VERSION ""

NS_ :

BS_:

BU_: OpticalSensor SCIMO_PE TelemetryNode Master Sensor Brake PDU TestBench

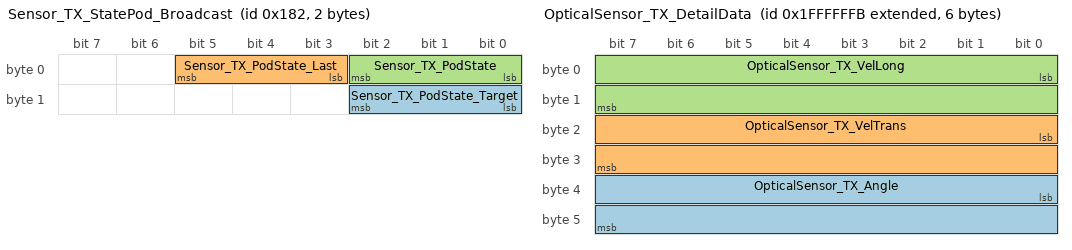
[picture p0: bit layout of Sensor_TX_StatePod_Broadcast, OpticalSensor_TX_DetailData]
BO_ 386 Sensor_TX_StatePod_Broadcast: 2 Vector__XXX
 SG_ Sensor_TX_PodState_Target : 8|3@1+ (1,0) [0|0] "" Vector__XXX
 SG_ Sensor_TX_PodState_Last : 3|3@1+ (1,0) [0|0] "" Vector__XXX
 SG_ Sensor_TX_PodState : 0|3@1+ (1,0) [0|0] "" Vector__XXX

BO_ 1026 Sensor_TX_GapHeight: 4 Vector__XXX
 SG_ Sensor_TX_GapHeight_Right : 12|12@1- (0.0125,0) [-25.6|25.5875] "mm" Vector__XXX
 SG_ Sensor_TX_GapHeight_Left : 0|12@1- (0.0125,0) [-25.6|25.5875] "mm" Vector__XXX

BO_ 450 Sensor_RX_POD1: 8 Vector__XXX

BO_ 2684354555 OpticalSensor_TX_DetailData: 6 OpticalSensor
 SG_ OpticalSensor_TX_Angle : 32|16@1- (0.01,0) [-45|45] "�" Vector__XXX
 SG_ OpticalSensor_TX_VelTrans : 16|16@1- (0.036,0) [-200|200] "km/h" Vector__XXX
 SG_ OpticalSensor_TX_VelLong : 0|16@1+ (0.036,0) [0|400] "km/h" Vector__XXX

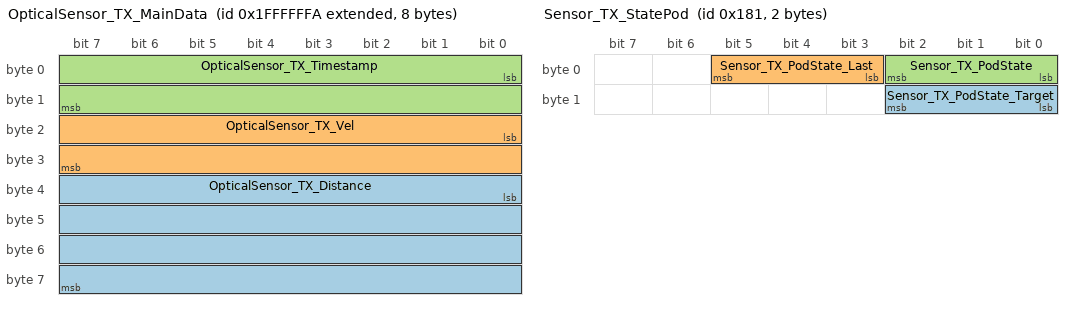
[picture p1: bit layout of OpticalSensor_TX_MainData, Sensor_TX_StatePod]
BO_ 2684354554 OpticalSensor_TX_MainData: 8 OpticalSensor
 SG_ OpticalSensor_TX_Distance : 32|32@1+ (0.001,0) [0|4294970] "m" Vector__XXX
 SG_ OpticalSensor_TX_Vel : 16|16@1+ (0.036,0) [0|400] "km/h" Vector__XXX
 SG_ OpticalSensor_TX_Timestamp : 0|16@1+ (1,0) [0|65535] "" Vector__XXX

BO_ 2684354556 OpticalSensor_TX_Status: 8 OpticalSensor
 SG_ OpticalSensor_TX_VddOK : 62|1@1+ (1,0) [0|0] "" Vector__XXX
 SG_ OpticalSensor_TX_VeeOK : 61|1@1+ (1,0) [0|0] "" Vector__XXX
 SG_ OpticalSensor_TX_V33OK : 60|1@1+ (1,0) [0|0] "" Vector__XXX
 SG_ OpticalSensor_TX_V25OK : 59|1@1+ (1,0) [0|0] "" Vector__XXX
 SG_ OpticalSensor_TX_LEDStatus : 57|2@1+ (1,0) [0|0] "" Vector__XXX
 SG_ OpticalSensor_TX_LED_Cal : 56|1@1+ (1,0) [0|0] "" Vector__XXX
 SG_ OpticalSensor_TX_PowerOK : 55|1@1+ (1,0) [0|0] "" Vector__XXX
 SG_ OpticalSensor_TX_CurrentOK : 54|1@1+ (1,0) [0|0] "" Vector__XXX
 SG_ OpticalSensor_TX_CurrentLowHigh : 53|1@1+ (1,0) [0|0] "" Vector__XXX
 SG_ OpticalSensor_TX_OpticOK : 52|1@1+ (1,0) [0|0] "" Vector__XXX
 SG_ OpticalSensor_TX_TempOK : 51|1@1+ (1,0) [0|0] "" Vector__XXX
 SG_ OpticalSensor_TX_SensorOK : 50|1@1+ (1,0) [0|0] "" Vector__XXX
 SG_ OpticalSensor_TX_SelfTest : 49|1@1+ (1,0) [0|0] "" Vector__XXX
 SG_ OpticalSensor_TX_STST : 48|1@1+ (1,0) [0|0] "" Vector__XXX
 SG_ OpticalSensor_TX_LEDCurrent : 40|8@1+ (0.01,0) [0|2.55] "A" Vector__XXX
 SG_ OpticalSensor_TX_Temp : 32|8@1- (1,0) [-128|127] "�C" Vector__XXX
 SG_ OpticalSensor_TX_SensorNo : 24|8@1+ (1,0) [0|0] "" Vector__XXX
 SG_ OpticalSensor_TX_SerialNo : 0|24@1+ (1,0) [0|0] "" Vector__XXX

BO_ 2 CANzero_NMT: 4 Master
 SG_ CANzero_NMT_Node : 16|16@1+ (1,0) [0|63] ""  Sensor,Brake,PDU,TelemetryNode
 SG_ CANzero_NMT_State : 0|16@1+ (1,0) [0|0] ""  Sensor,Brake,PDU,TelemetryNode

BO_ 122 CANzero_Sync: 0 Master

BO_ 123 CANzero_Timestamp: 0 Master

BO_ 129 Sensor_EMCY: 4 Sensor

BO_ 385 Sensor_TX_StatePod: 2 Sensor
 SG_ Sensor_TX_PodState_Target : 8|3@1+ (1,0) [0|0] ""  PDU
 SG_ Sensor_TX_PodState_Last : 3|3@1+ (1,0) [0|0] ""  PDU
 SG_ Sensor_TX_PodState : 0|3@1+ (1,0) [0|0] ""  PDU

BO_ 449 Sensor_RX_PDO1: 0 Vector__XXX

BO_ 513 Sensor_TX_FSMTransitions: 4 Sensor
 SG_ Sensor_TX_PreopHVCUT : 24|1@1+ (1,0) [0|0] "" Vector__XXX
 SG_ Sensor_TX_PreopPDUT : 16|1@1+ (1,0) [0|0] "" Vector__XXX
 SG_ Sensor_TX_PreopBrakeRT : 15|1@1+ (1,0) [0|0] "" Vector__XXX
 SG_ Sensor_TX_PreopBrakeFT : 14|1@1+ (1,0) [0|0] "" Vector__XXX
 SG_ Sensor_TX_PreopSensorRT : 13|1@1+ (1,0) [0|0] "" Vector__XXX
 SG_ Sensor_TX_EnableSensorRT : 12|1@1+ (1,0) [0|0] "" Vector__XXX
 SG_ Sensor_TX_EnablePDUT : 11|1@1+ (1,0) [0|0] "" Vector__XXX
 SG_ Sensor_TX_EnableHVCUT : 10|1@1+ (1,0) [0|0] "" Vector__XXX
 SG_ Sensor_TX_EnableBrakeRT : 9|1@1+ (1,0) [0|0] "" Vector__XXX
 SG_ Sensor_TX_EnableBrakeFT : 8|1@1+ (1,0) [0|0] "" Vector__XXX
 SG_ Sensor_TX_SetHVTransition : 7|1@1+ (1,0) [0|0] "" Vector__XXX
 SG_ Sensor_TX_PreopTransition : 6|1@1+ (1,0) [0|0] "" Vector__XXX
 SG_ Sensor_TX_LaunchStartTransition : 5|1@1+ (1,0) [0|0] "" Vector__XXX
 SG_ Sensor_TX_LaunchSetupTransition : 4|1@1+ (1,0) [0|0] "" Vector__XXX
 SG_ Sensor_TX_HWEnableTransition : 3|1@1+ (1,0) [0|0] "" Vector__XXX
 SG_ Sensor_TX_ErrorResetTransition : 2|1@1+ (1,0) [0|0] "" Vector__XXX
 SG_ Sensor_TX_EnableTransition : 1|1@1+ (1,0) [0|0] "" Vector__XXX
 SG_ Sensor_TX_BrakesTransition : 0|1@1+ (1,0) [0|0] "" Vector__XXX

BO_ 577 Sensor_RX_PDO2: 0 Vector__XXX

BO_ 641 Sensor_TX_PDO3: 0 Sensor

BO_ 705 Sensor_RX_PDO3: 0 Vector__XXX

BO_ 769 Sensor_TX_PDO4: 0 Sensor

BO_ 833 Sensor_RX_PDO4: 0 Vector__XXX

BO_ 897 Sensor_TX_PDO5: 0 Sensor

BO_ 961 Sensor_TX_PDO6: 0 Sensor

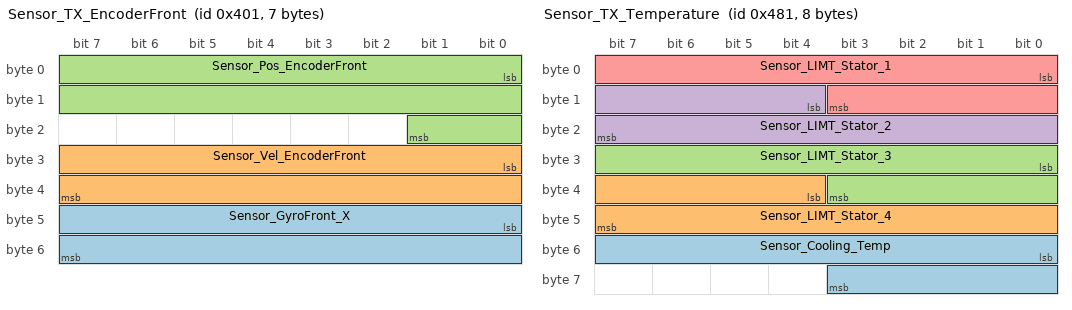
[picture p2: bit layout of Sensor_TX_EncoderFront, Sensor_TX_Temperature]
BO_ 1025 Sensor_TX_EncoderFront: 7 Sensor
 SG_ Sensor_GyroFront_X : 40|16@1- (0.017,0) [-557.056|557.039] "°/s" Vector__XXX
 SG_ Sensor_Vel_EncoderFront : 24|16@1- (0.002,0) [-65.536|65.534] "m/s" Vector__XXX
 SG_ Sensor_Pos_EncoderFront : 0|18@1- (0.005,0) [-655.36|655.355] "m" Vector__XXX

BO_ 1089 Sensor_TX_BMS: 2 Sensor
 SG_ Sensor_TX_BatteryTemp : 0|12@1+ (0.05,-30) [-30|174.75] "C"  PDU

BO_ 1153 Sensor_TX_Temperature: 8 Sensor
 SG_ Sensor_Cooling_Temp : 48|12@1+ (0.05,-30) [-30|174.75] "C"  PDU
 SG_ Sensor_LIMT_Stator_4 : 36|12@1+ (0.075,-20) [-20|287.125] "�C" Vector__XXX
 SG_ Sensor_LIMT_Stator_3 : 24|12@1+ (0.075,-20) [-20|287.125] "�C" Vector__XXX
 SG_ Sensor_LIMT_Stator_2 : 12|12@1+ (0.075,-20) [-20|287.125] "�C" Vector__XXX
 SG_ Sensor_LIMT_Stator_1 : 0|12@1+ (0.075,-20) [-20|287.125] "�C" Vector__XXX

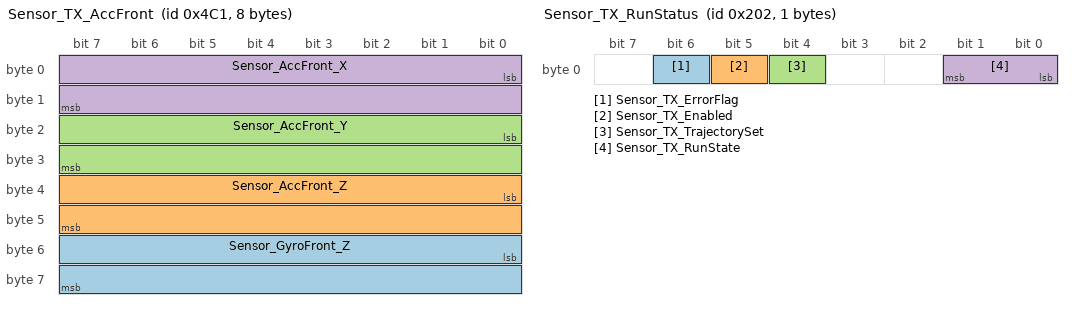
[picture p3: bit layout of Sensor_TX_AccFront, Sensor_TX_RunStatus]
BO_ 1217 Sensor_TX_AccFront: 8 Sensor
 SG_ Sensor_GyroFront_Z : 48|16@1- (0.017,0) [-557.056|557.039] "°/s" Vector__XXX
 SG_ Sensor_AccFront_Z : 32|16@1- (0.00125,0) [-40.96|40.95875] "m/s^2" Vector__XXX
 SG_ Sensor_AccFront_Y : 16|16@1- (0.00125,0) [-40.96|40.95875] "m/s^2" Vector__XXX
 SG_ Sensor_AccFront_X : 0|16@1- (0.00125,0) [-40.96|40.95875] "m/s^2" Vector__XXX

BO_ 1281 Sensor_TX_PDO11: 0 Sensor

BO_ 1345 Sensor_TX_PDO12: 0 Sensor

BO_ 1409 Sensor_SDO_Resp: 8 Sensor
 SG_ Sensor_SDO_RespCode : 12|4@1+ (1,0) [0|0] ""  TelemetryNode
 SG_ Sensor_SDO_ID M : 0|12@1+ (1,0) [0|4095] ""  TelemetryNode

BO_ 1473 Sensor_SDO_Req_Up: 8 TelemetryNode
 SG_ Sensor_SDO_ID M : 0|12@1+ (1,0) [0|4095] ""  Sensor

BO_ 1537 Sensor_SDO_Req_Down: 2 TelemetryNode
 SG_ Sensor_SDO_ID M : 0|12@1+ (1,0) [0|4095] ""  Sensor

BO_ 1793 Sensor_Heartbeat: 1 Sensor
 SG_ Sensor_NodeState : 0|8@1+ (1,0) [0|0] ""  Sensor,Master,TelemetryNode

BO_ 1857 Sensor_BTL_TX: 8 Sensor

BO_ 1921 Sensor_BTL_RX: 8 TelemetryNode

BO_ 514 Sensor_TX_RunStatus: 1 Vector__XXX
 SG_ Sensor_TX_ErrorFlag : 6|1@1+ (1,0) [0|0] ""  Sensor
 SG_ Sensor_TX_Enabled : 5|1@1+ (1,0) [0|0] ""  Sensor
 SG_ Sensor_TX_TrajectorySet : 4|1@1+ (1,0) [0|0] "" Vector__XXX
 SG_ Sensor_TX_RunState : 0|2@1+ (1,0) [0|0] ""  PDU,Sensor

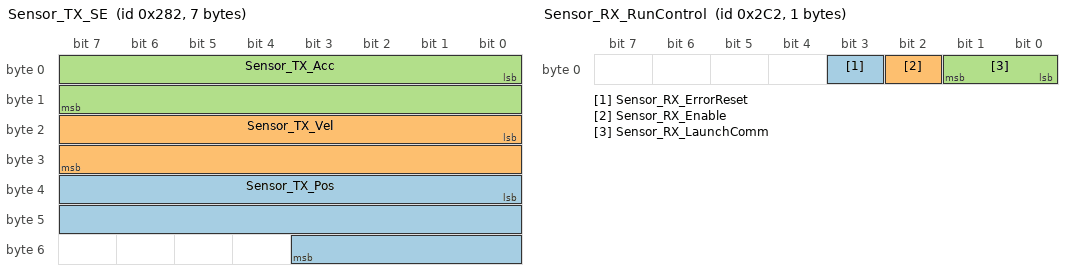
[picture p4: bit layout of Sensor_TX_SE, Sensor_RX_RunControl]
BO_ 642 Sensor_TX_SE: 7 Vector__XXX
 SG_ Sensor_TX_Pos : 32|20@1- (0.001,0) [-524.288|524.287] "m"  PDU,TelemetryNode
 SG_ Sensor_TX_Vel : 16|16@1- (0.002,0) [-65.536|65.534] "m/s"  PDU,TelemetryNode
 SG_ Sensor_TX_Acc : 0|16@1- (0.00125,0) [-40.96|40.95875] "m/s^2"  PDU,TelemetryNode

BO_ 706 Sensor_RX_RunControl: 1 Sensor
 SG_ Sensor_RX_ErrorReset : 3|1@1+ (1,0) [0|0] "" Vector__XXX
 SG_ Sensor_RX_Enable : 2|1@1+ (1,0) [0|0] "" Vector__XXX
 SG_ Sensor_RX_LaunchComm : 0|2@1+ (1,0) [0|0] "" Vector__XXX

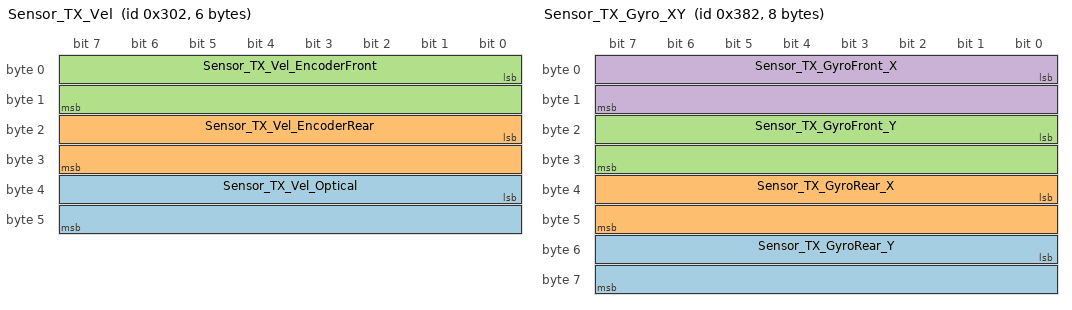
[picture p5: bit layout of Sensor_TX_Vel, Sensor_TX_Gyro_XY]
BO_ 770 Sensor_TX_Vel: 6 Vector__XXX
 SG_ Sensor_TX_Vel_Optical : 32|16@1- (0.002,0) [-65.536|65.534] "m/s" Vector__XXX
 SG_ Sensor_TX_Vel_EncoderRear : 16|16@1- (0.002,0) [-65.536|65.534] "m/s" Vector__XXX
 SG_ Sensor_TX_Vel_EncoderFront : 0|16@1- (0.002,0) [-65.536|65.534] "m/s" Vector__XXX

BO_ 898 Sensor_TX_Gyro_XY: 8 Vector__XXX
 SG_ Sensor_TX_GyroRear_Y : 48|16@1- (0.017,0) [-557.056|557.039] "°/s" Vector__XXX
 SG_ Sensor_TX_GyroRear_X : 32|16@1- (0.017,0) [-557.056|557.039] "°/s" Vector__XXX
 SG_ Sensor_TX_GyroFront_Y : 16|16@1- (0.017,0) [-557.056|557.039] "°/s" Vector__XXX
 SG_ Sensor_TX_GyroFront_X : 0|16@1- (0.017,0) [-557.056|557.039] "°/s" Vector__XXX

BO_ 962 Sensor_TX_TargetValues: 2 Vector__XXX
 SG_ Sensor_TX_TargetVelocity : 0|14@1- (0.01,0) [-81.92|81.91] "m/s" Vector__XXX

BO_ 1090 Sensor_TX_PDO8: 0 Vector__XXX

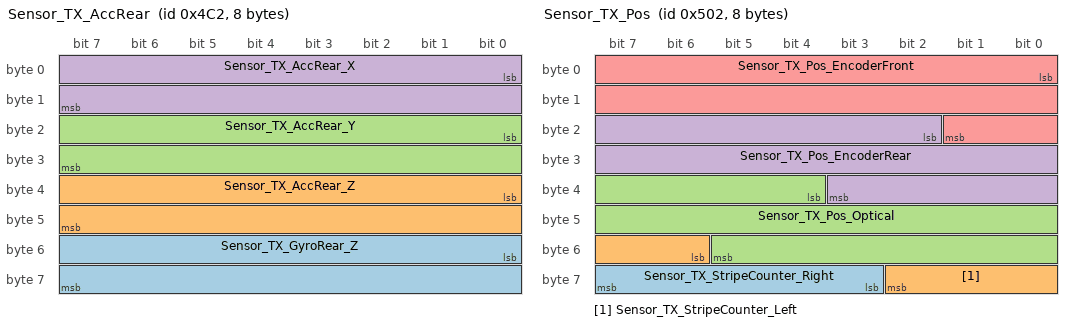
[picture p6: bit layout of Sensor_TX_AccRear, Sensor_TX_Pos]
BO_ 1218 Sensor_TX_AccRear: 8 Vector__XXX
 SG_ Sensor_TX_GyroRear_Z : 48|16@1- (0.017,0) [-557.056|557.039] "°/s" Vector__XXX
 SG_ Sensor_TX_AccRear_Z : 32|16@1- (0.00125,0) [-40.96|40.95875] "m/s^2" Vector__XXX
 SG_ Sensor_TX_AccRear_Y : 16|16@1- (0.00125,0) [-40.96|40.95875] "m/s^2" Vector__XXX
 SG_ Sensor_TX_AccRear_X : 0|16@1- (0.00125,0) [-40.96|40.95875] "m/s^2" Vector__XXX

BO_ 1282 Sensor_TX_Pos: 8 Vector__XXX
 SG_ Sensor_TX_StripeCounter_Right : 59|5@1+ (1,0) [0|31] "" Vector__XXX
 SG_ Sensor_TX_StripeCounter_Left : 54|5@1+ (1,0) [0|31] "" Vector__XXX
 SG_ Sensor_TX_Pos_Optical : 36|18@1- (0.005,0) [-655.36|655.355] "m" Vector__XXX
 SG_ Sensor_TX_Pos_EncoderRear : 18|18@1- (0.005,0) [-655.36|655.355] "m" Vector__XXX
 SG_ Sensor_TX_Pos_EncoderFront : 0|18@1- (0.005,0) [-655.36|655.355] "m" Vector__XXX

BO_ 145 Brake_EMCY: 4 Brake

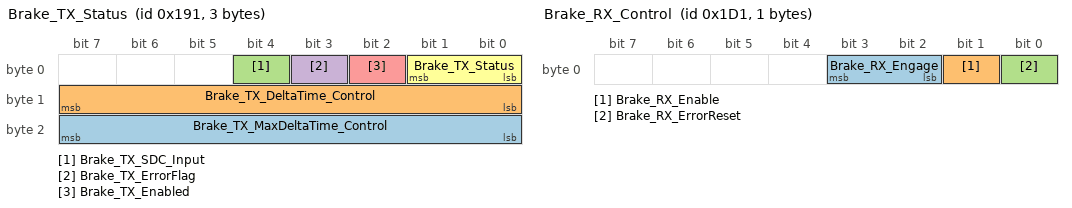
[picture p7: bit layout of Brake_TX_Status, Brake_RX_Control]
BO_ 401 Brake_TX_Status: 3 Brake
 SG_ Brake_TX_MaxDeltaTime_Control : 16|8@1+ (1,0) [0|255] "ms" Vector__XXX
 SG_ Brake_TX_DeltaTime_Control : 8|8@1+ (1,0) [0|255] "ms" Vector__XXX
 SG_ Brake_TX_SDC_Input : 4|1@1+ (1,0) [0|0] "" Vector__XXX
 SG_ Brake_TX_ErrorFlag : 3|1@1+ (1,0) [0|0] ""  Sensor
 SG_ Brake_TX_Enabled : 2|1@1+ (1,0) [0|0] ""  Sensor
 SG_ Brake_TX_Status : 0|2@1+ (1,0) [0|0] ""  Sensor

BO_ 465 Brake_RX_Control: 1 Sensor
 SG_ Brake_RX_Engage : 2|2@1+ (1,0) [0|0] "" Vector__XXX
 SG_ Brake_RX_Enable : 1|1@1+ (1,0) [0|0] "" Vector__XXX
 SG_ Brake_RX_ErrorReset : 0|1@1+ (1,0) [0|0] "" Vector__XXX

BO_ 529 Brake_TX_PDO2: 0 Brake

BO_ 593 Brake_RX_PDO2: 0 Vector__XXX

BO_ 657 Brake_TX_PDO3: 0 Brake

BO_ 721 Brake_RX_PDO3: 0 Vector__XXX

BO_ 785 Brake_TX_PDO4: 0 Brake

BO_ 849 Brake_RX_PDO4: 0 Vector__XXX

BO_ 913 Brake_TX_PDO5: 0 Brake

BO_ 977 Brake_TX_PDO6: 0 Brake

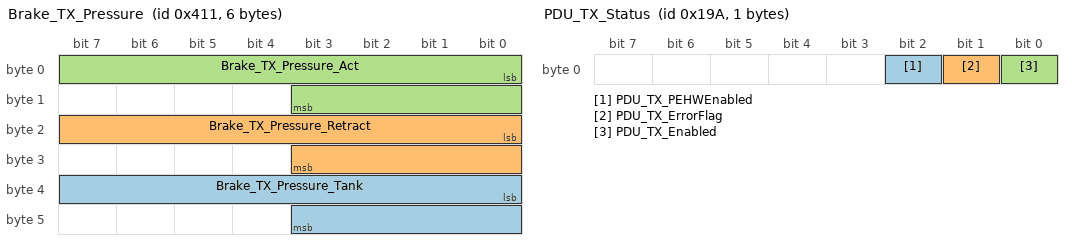
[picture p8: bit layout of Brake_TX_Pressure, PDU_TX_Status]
BO_ 1041 Brake_TX_Pressure: 6 Brake
 SG_ Brake_TX_Pressure_Tank : 32|12@1+ (0.005,-2) [-2|18.475] "bar" Vector__XXX
 SG_ Brake_TX_Pressure_Retract : 16|12@1+ (0.005,-2) [-2|18.475] "bar" Vector__XXX
 SG_ Brake_TX_Pressure_Act : 0|12@1+ (0.005,-2) [-2|18.475] "bar" Vector__XXX

BO_ 1105 Brake_TX_PDO8: 0 Brake

BO_ 1169 Brake_TX_PDO9: 0 Brake

BO_ 1233 Brake_TX_PDO10: 0 Brake

BO_ 1297 Brake_TX_PDO11: 0 Brake

BO_ 1361 Brake_TX_PDO12: 0 Brake

BO_ 1425 Brake_SDO_Resp: 8 Brake
 SG_ Brake_SDO_RespCode : 12|4@1+ (1,0) [0|0] ""  TelemetryNode
 SG_ Brake_SDO_ID M : 0|12@1+ (1,0) [0|4095] ""  TelemetryNode

BO_ 1489 Brake_SDO_Req_Up: 8 TelemetryNode
 SG_ Brake_SDO_ID M : 0|12@1+ (1,0) [0|4095] ""  Brake

BO_ 1553 Brake_SDO_Req_Down: 2 TelemetryNode
 SG_ Brake_SDO_ID M : 0|12@1+ (1,0) [0|4095] ""  Brake

BO_ 1809 Brake_Heartbeat: 1 Brake
 SG_ Brake_NodeState : 0|8@1+ (1,0) [0|0] ""  Sensor,Master,TelemetryNode

BO_ 1873 Brake_BTL_TX: 8 Brake

BO_ 1937 Brake_BTL_RX: 8 TelemetryNode

BO_ 154 PDU_EMCY: 4 PDU

BO_ 410 PDU_TX_Status: 1 PDU
 SG_ PDU_TX_PEHWEnabled : 2|1@1+ (1,0) [0|0] ""  Sensor
 SG_ PDU_TX_ErrorFlag : 1|1@1+ (1,0) [0|0] ""  Sensor
 SG_ PDU_TX_Enabled : 0|1@1+ (1,0) [0|0] ""  Sensor

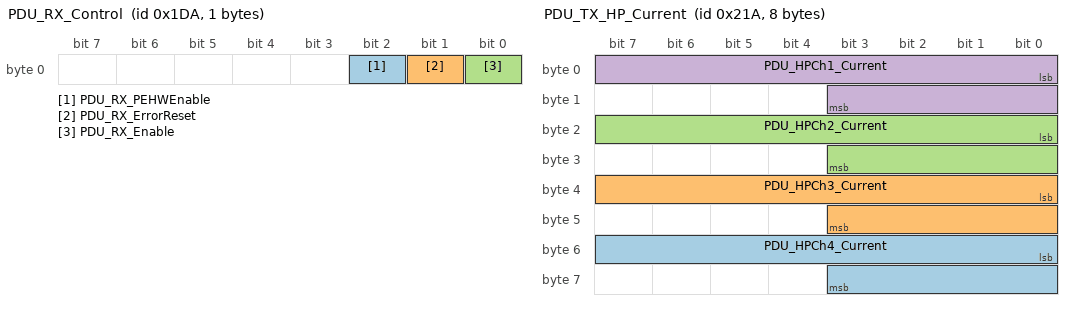
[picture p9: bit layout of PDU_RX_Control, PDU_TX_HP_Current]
BO_ 474 PDU_RX_Control: 1 Sensor
 SG_ PDU_RX_PEHWEnable : 2|1@1+ (1,0) [0|0] "" Vector__XXX
 SG_ PDU_RX_ErrorReset : 1|1@1+ (1,0) [0|0] "" Vector__XXX
 SG_ PDU_RX_Enable : 0|1@1+ (1,0) [0|0] "" Vector__XXX

BO_ 538 PDU_TX_HP_Current: 8 PDU
 SG_ PDU_HPCh4_Current : 48|12@1+ (0.004,0) [0|16.38] "A" Vector__XXX
 SG_ PDU_HPCh3_Current : 32|12@1+ (0.004,0) [0|16.38] "A" Vector__XXX
 SG_ PDU_HPCh2_Current : 16|12@1+ (0.004,0) [0|16.38] "A" Vector__XXX
 SG_ PDU_HPCh1_Current : 0|12@1+ (0.004,0) [0|16.38] "A" Vector__XXX

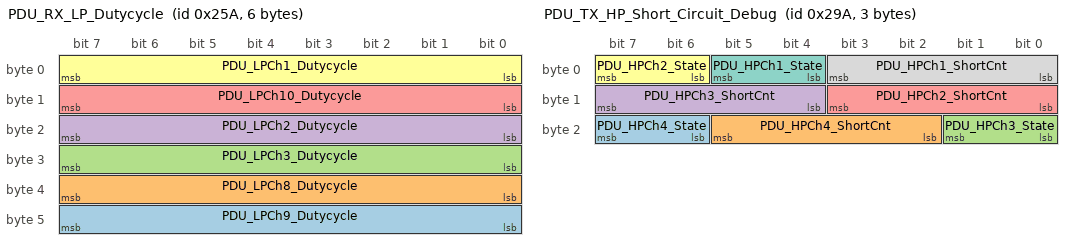
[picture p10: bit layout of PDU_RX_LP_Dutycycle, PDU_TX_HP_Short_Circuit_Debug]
BO_ 602 PDU_RX_LP_Dutycycle: 6 Vector__XXX
 SG_ PDU_LPCh9_Dutycycle : 40|8@1+ (0.5,0) [0|100] "%" Vector__XXX
 SG_ PDU_LPCh8_Dutycycle : 32|8@1+ (0.5,0) [0|100] "%" Vector__XXX
 SG_ PDU_LPCh3_Dutycycle : 24|8@1+ (0.5,0) [0|100] "%" Vector__XXX
 SG_ PDU_LPCh2_Dutycycle : 16|8@1+ (0.5,0) [0|100] "%" Vector__XXX
 SG_ PDU_LPCh10_Dutycycle : 8|8@1+ (0.5,0) [0|100] "%" Vector__XXX
 SG_ PDU_LPCh1_Dutycycle : 0|8@1+ (0.5,0) [0|100] "%" Vector__XXX

BO_ 666 PDU_TX_HP_Short_Circuit_Debug: 3 PDU
 SG_ PDU_HPCh4_State : 22|2@1+ (1,0) [0|3] "" Vector__XXX
 SG_ PDU_HPCh4_ShortCnt : 18|4@1+ (1,0) [0|15] "" Vector__XXX
 SG_ PDU_HPCh3_State : 16|2@1+ (1,0) [0|3] "" Vector__XXX
 SG_ PDU_HPCh3_ShortCnt : 12|4@1+ (1,0) [0|15] "" Vector__XXX
 SG_ PDU_HPCh2_ShortCnt : 8|4@1+ (1,0) [0|15] "" Vector__XXX
 SG_ PDU_HPCh2_State : 6|2@1+ (1,0) [0|3] "" Vector__XXX
 SG_ PDU_HPCh1_State : 4|2@1+ (1,0) [0|3] "" Vector__XXX
 SG_ PDU_HPCh1_ShortCnt : 0|4@1+ (1,0) [0|15] "" Vector__XXX

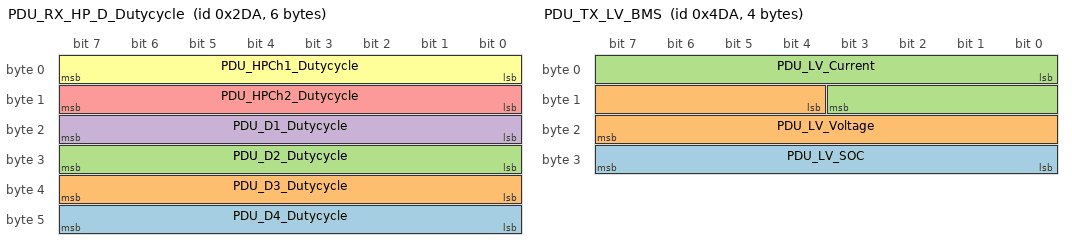
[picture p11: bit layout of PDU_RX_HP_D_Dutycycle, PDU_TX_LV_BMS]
BO_ 730 PDU_RX_HP_D_Dutycycle: 6 Vector__XXX
 SG_ PDU_D4_Dutycycle : 40|8@1+ (0.5,0) [0|100] "%" Vector__XXX
 SG_ PDU_D3_Dutycycle : 32|8@1+ (0.5,0) [0|100] "%" Vector__XXX
 SG_ PDU_D2_Dutycycle : 24|8@1+ (0.5,0) [0|100] "%" Vector__XXX
 SG_ PDU_D1_Dutycycle : 16|8@1+ (0.5,0) [0|100] "%" Vector__XXX
 SG_ PDU_HPCh2_Dutycycle : 8|8@1+ (0.5,0) [0|100] "%" Vector__XXX
 SG_ PDU_HPCh1_Dutycycle : 0|8@1+ (0.5,0) [0|100] "%" Vector__XXX

BO_ 794 PDU_TX_PDO4: 0 PDU

BO_ 858 PDU_RX_Manual_Control: 3 Vector__XXX
 SG_ PDU_SDC_Enable : 18|1@1+ (1,0) [0|0] "" Vector__XXX
 SG_ PDU_D4_Enable : 17|1@1+ (1,0) [0|1] "" Vector__XXX
 SG_ PDU_D3_Enable : 16|1@1+ (1,0) [0|1] "" Vector__XXX
 SG_ PDU_D2_Enable : 15|1@1+ (1,0) [0|1] "" Vector__XXX
 SG_ PDU_D1_Enable : 14|1@1+ (1,0) [0|1] "" Vector__XXX
 SG_ PDU_HPCh4_Enable : 13|1@1+ (1,0) [0|1] "" Vector__XXX
 SG_ PDU_HPCh3_Enable : 12|1@1+ (1,0) [0|1] "" Vector__XXX
 SG_ PDU_HPCh2_Enable : 11|1@1+ (1,0) [0|1] "" Vector__XXX
 SG_ PDU_HPCh1_Enable : 10|1@1+ (1,0) [0|1] "" Vector__XXX
 SG_ PDU_LPCh10_Enable : 9|1@1+ (1,0) [0|1] "" Vector__XXX
 SG_ PDU_LPCh9_Enable : 8|1@1+ (1,0) [0|1] "" Vector__XXX
 SG_ PDU_LPCh8_Enable : 7|1@1+ (1,0) [0|1] "" Vector__XXX
 SG_ PDU_LPCh7_Enable : 6|1@1+ (1,0) [0|1] "" Vector__XXX
 SG_ PDU_LPCh6_Enable : 5|1@1+ (1,0) [0|1] "" Vector__XXX
 SG_ PDU_LPCh5_Enable : 4|1@1+ (1,0) [0|1] "" Vector__XXX
 SG_ PDU_LPCh4_Enable : 3|1@1+ (1,0) [0|1] "" Vector__XXX
 SG_ PDU_LPCh3_Enable : 2|1@1+ (1,0) [0|1] "" Vector__XXX
 SG_ PDU_LPCh2_Enable : 1|1@1+ (1,0) [0|1] "" Vector__XXX
 SG_ PDU_LPCh1_Enable : 0|1@1+ (1,0) [0|1] "" Vector__XXX

BO_ 922 PDU_TX_PDO5: 0 PDU

BO_ 986 PDU_TX_PDO6: 0 PDU

BO_ 1050 PDU_TX_PDO7: 0 PDU

BO_ 1114 PDU_TX_PDO8: 0 PDU

BO_ 1178 PDU_TX_LP_Short_Circuit_Debug: 8 PDU
 SG_ PDU_LPCh9_State : 58|2@1+ (1,0) [0|3] "" Vector__XXX
 SG_ PDU_LPCh8_State : 56|2@1+ (1,0) [0|3] "" Vector__XXX
 SG_ PDU_LPCh7_State : 54|2@1+ (1,0) [0|3] "" Vector__XXX
 SG_ PDU_LPCh6_State : 52|2@1+ (1,0) [0|3] "" Vector__XXX
 SG_ PDU_LPCh5_State : 50|2@1+ (1,0) [0|3] "" Vector__XXX
 SG_ PDU_LPCh4_State : 48|2@1+ (1,0) [0|3] "" Vector__XXX
 SG_ PDU_LPCh3_State : 46|2@1+ (1,0) [0|3] "" Vector__XXX
 SG_ PDU_LPCh2_State : 44|2@1+ (1,0) [0|3] "" Vector__XXX
 SG_ PDU_LPCh1_State : 42|2@1+ (1,0) [0|3] "" Vector__XXX
 SG_ PDU_LPCh10_State : 40|2@1+ (1,0) [0|3] "" Vector__XXX
 SG_ PDU_LPCh9_ShortCnt : 36|4@1+ (1,0) [0|15] "" Vector__XXX
 SG_ PDU_LPCh8_ShortCnt : 32|4@1+ (1,0) [0|15] "" Vector__XXX
 SG_ PDU_LPCh7_ShortCnt : 28|4@1+ (1,0) [0|15] "" Vector__XXX
 SG_ PDU_LPCh6_ShortCnt : 24|4@1+ (1,0) [0|15] "" Vector__XXX
 SG_ PDU_LPCh5_ShortCnt : 20|4@1+ (1,0) [0|15] "" Vector__XXX
 SG_ PDU_LPCh4_ShortCnt : 16|4@1+ (1,0) [0|15] "" Vector__XXX
 SG_ PDU_LPCh3_ShortCnt : 12|4@1+ (1,0) [0|15] "" Vector__XXX
 SG_ PDU_LPCh2_ShortCnt : 8|4@1+ (1,0) [0|15] "" Vector__XXX
 SG_ PDU_LPCh1_ShortCnt : 4|4@1+ (1,0) [0|15] "" Vector__XXX
 SG_ PDU_LPCh10_ShortCnt : 0|4@1+ (1,0) [0|15] "" Vector__XXX

BO_ 1242 PDU_TX_LV_BMS: 4 PDU
 SG_ PDU_LV_SOC : 24|8@1- (1,0) [0|100] "%" Vector__XXX
 SG_ PDU_LV_Voltage : 12|12@1+ (0.01,0) [0|40.95] "V" Vector__XXX
 SG_ PDU_LV_Current : 0|12@1+ (0.01,0) [0|40.95] "A" Vector__XXX

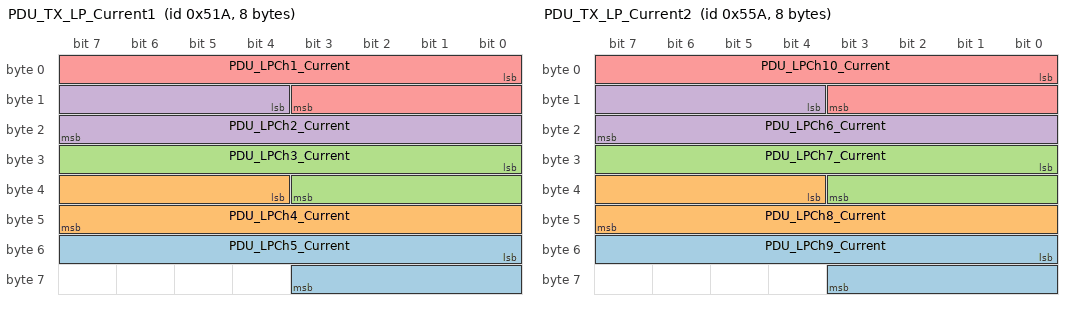
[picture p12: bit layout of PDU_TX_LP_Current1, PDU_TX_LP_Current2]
BO_ 1306 PDU_TX_LP_Current1: 8 PDU
 SG_ PDU_LPCh5_Current : 48|12@1+ (0.002,0) [0|8.19] "A" Vector__XXX
 SG_ PDU_LPCh4_Current : 36|12@1+ (0.002,0) [0|8.19] "A" Vector__XXX
 SG_ PDU_LPCh3_Current : 24|12@1+ (0.002,0) [0|8.19] "A" Vector__XXX
 SG_ PDU_LPCh2_Current : 12|12@1+ (0.002,0) [0|8.19] "A" Vector__XXX
 SG_ PDU_LPCh1_Current : 0|12@1+ (0.002,0) [0|8.19] "A" Vector__XXX

BO_ 1370 PDU_TX_LP_Current2: 8 PDU
 SG_ PDU_LPCh9_Current : 48|12@1+ (0.002,0) [0|8.19] "A" Vector__XXX
 SG_ PDU_LPCh8_Current : 36|12@1+ (0.002,0) [0|8.19] "A" Vector__XXX
 SG_ PDU_LPCh7_Current : 24|12@1+ (0.002,0) [0|8.19] "A" Vector__XXX
 SG_ PDU_LPCh6_Current : 12|12@1+ (0.002,0) [0|8.19] "A" Vector__XXX
 SG_ PDU_LPCh10_Current : 0|12@1+ (0.002,0) [0|8.19] "A" Vector__XXX

BO_ 1434 PDU_SDO_Resp: 8 PDU
 SG_ PDU_SDO_RespCode : 12|4@1+ (1,0) [0|0] ""  TelemetryNode
 SG_ PDU_SDO_ID M : 0|12@1+ (1,0) [0|4095] ""  TelemetryNode

BO_ 1498 PDU_SDO_Req_Up: 8 TelemetryNode
 SG_ PDU_SDO_ID M : 0|12@1+ (1,0) [0|4095] ""  PDU

BO_ 1562 PDU_SDO_Req_Down: 2 TelemetryNode
 SG_ PDU_SDO_ID M : 0|12@1+ (1,0) [0|4095] ""  PDU

BO_ 1818 PDU_Heartbeat: 1 PDU
 SG_ PDU_NodeState : 0|8@1+ (1,0) [0|0] ""  Sensor,Master,TelemetryNode

BO_ 1882 PDU_BTL_TX: 8 PDU

BO_ 1946 PDU_BTL_RX: 8 TelemetryNode

BO_ 162 TelemetryNode_EMCY: 4 TelemetryNode

BO_ 418 TelemetryNode_TX_PDO1: 0 TelemetryNode

BO_ 482 TelemetryNode_RX_Shutdown: 1 Vector__XXX
 SG_ TelemetryNode_RX_Shutdown : 0|8@1+ (1,0) [0|0] "" Vector__XXX

BO_ 546 TelemetryNode_TX_PDO2: 0 TelemetryNode

BO_ 610 TelemetryNode_RX_PDO2: 0 Vector__XXX

BO_ 674 TelemetryNode_TX_PDO3: 0 TelemetryNode

BO_ 738 TelemetryNode_RX_PDO3: 0 Vector__XXX

BO_ 802 TelemetryNode_TX_PDO4: 0 TelemetryNode

BO_ 866 TelemetryNode_RX_PDO4: 0 Vector__XXX

BO_ 930 TelemetryNode_TX_PDO5: 0 TelemetryNode

BO_ 994 TelemetryNode_TX_PDO6: 0 TelemetryNode

BO_ 1058 TelemetryNode_TX_PDO7: 0 TelemetryNode

BO_ 1122 TelemetryNode_TX_PDO8: 0 TelemetryNode

BO_ 1186 TelemetryNode_TX_PDO9: 0 TelemetryNode

BO_ 1250 TelemetryNode_TX_PDO10: 0 TelemetryNode

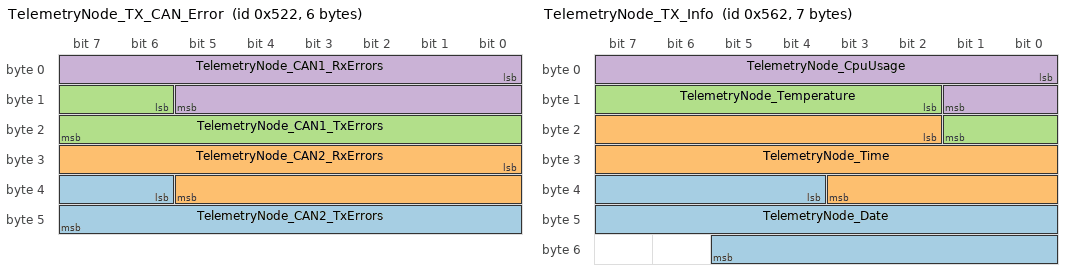
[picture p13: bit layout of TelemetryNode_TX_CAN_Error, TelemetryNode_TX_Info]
BO_ 1314 TelemetryNode_TX_CAN_Error: 6 TelemetryNode
 SG_ TelemetryNode_CAN2_TxErrors : 38|10@1+ (1,0) [0|4095] "" Vector__XXX
 SG_ TelemetryNode_CAN2_RxErrors : 24|14@1+ (1,0) [0|16383] "" Vector__XXX
 SG_ TelemetryNode_CAN1_TxErrors : 14|10@1+ (1,0) [0|4095] "" Vector__XXX
 SG_ TelemetryNode_CAN1_RxErrors : 0|14@1+ (1,0) [0|16383] "" Vector__XXX

BO_ 1378 TelemetryNode_TX_Info: 7 TelemetryNode
 SG_ TelemetryNode_Date : 36|18@1+ (1,20200000) [20200000|20462143] "" Vector__XXX
 SG_ TelemetryNode_Time : 18|18@1+ (1,0) [0|262143] "" Vector__XXX
 SG_ TelemetryNode_Temperature : 10|8@1+ (0.4,-10) [-10|92] "°C" Vector__XXX
 SG_ TelemetryNode_CpuUsage : 0|10@1+ (0.1,0) [0|102.3] "%" Vector__XXX

BO_ 1442 TelemetryNode_SDO_Resp: 8 TelemetryNode
 SG_ TelemetryNode_SDO_RespCode : 12|4@1+ (1,0) [0|0] ""  TelemetryNode
 SG_ TelemetryNode_SDO_ID M : 0|12@1+ (1,0) [0|4095] ""  TelemetryNode

BO_ 1506 TelemetryNode_SDO_Req_Up: 8 TelemetryNode
 SG_ TelemetryNode_SDO_ID M : 0|12@1+ (1,0) [0|4095] ""  TelemetryNode

BO_ 1570 TelemetryNode_SDO_Req_Down: 2 TelemetryNode
 SG_ TelemetryNode_SDO_ID M : 0|12@1+ (1,0) [0|4095] ""  TelemetryNode

BO_ 1826 TelemetryNode_Heartbeat: 1 TelemetryNode
 SG_ TelemetryNode_NodeState : 0|8@1+ (1,0) [0|0] ""  Sensor,Master,TelemetryNode

BO_ 1890 TelemetryNode_BTL_TX: 8 TelemetryNode

BO_ 1954 TelemetryNode_BTL_RX: 8 TelemetryNode

CM_ BU_ OpticalSensor "Kistler SFP-II optical Sensor.";
CM_ BU_ TelemetryNode "Gateway between Pod and Telemetry
Node-ID 0x22Gateway between Pod and Telemetry
Node-ID 0x22";
CM_ BU_ Master "CANzero NMT Master Node.";
CM_ BU_ Sensor "SensorECU
Node-ID 0x1";
CM_ BU_ Brake "BrakeECU
Node-ID 0x11";
CM_ BU_ PDU "PowerD
Node-ID 0x1A";
CM_ BO_ 386 "Transmit PDO 1 of node SensorF with Node-ID 0x1";
CM_ SG_ 386 Sensor_TX_PodState_Target "Target PodState by State Machine.";
CM_ SG_ 386 Sensor_TX_PodState_Last "Last PodState by State Machine.";
CM_ SG_ 386 Sensor_TX_PodState "PodState by State Machine.";
CM_ BO_ 1026 "Transmit PDO 7 of node SensorR with Node-ID 0x2. Gap Height of left and right sensor.";
CM_ SG_ 1026 Sensor_TX_GapHeight_Right "Gap height of LIM right.";
CM_ SG_ 1026 Sensor_TX_GapHeight_Left "Gap height of LIM left.";
CM_ BO_ 2684354555 "longitudinal and transverse velocity, angle between them";
CM_ SG_ 2684354555 OpticalSensor_TX_Angle "Angle between longitudianl and transverse direction.";
CM_ SG_ 2684354555 OpticalSensor_TX_VelTrans "Velocity in transverse direction.";
CM_ SG_ 2684354555 OpticalSensor_TX_VelLong "Velocity in longitudinal direction.";
CM_ BO_ 2684354554 "Timestamp, Veocity, Distance";
CM_ SG_ 2684354554 OpticalSensor_TX_Distance "Traveled distance";
CM_ SG_ 2684354554 OpticalSensor_TX_Vel "Absolute velocity";
CM_ BO_ 2684354556 "Timestamp, Veocity, Distance";
CM_ SG_ 2684354556 OpticalSensor_TX_Temp "Temperature of the sensor";
CM_ SG_ 2684354556 OpticalSensor_TX_SerialNo "Serialnumber of the sensor";
CM_ BO_ 2 "CANzero NMT message sent by NMT master.";
CM_ SG_ 2 CANzero_NMT_Node "CANzero NMT Node-ID of master request.";
CM_ SG_ 2 CANzero_NMT_State "CANzero NMT State Request by master.";
CM_ BO_ 122 "CANzero Sync message. Not used yet, just a placeholder for future versions.";
CM_ BO_ 123 "CANzero Timestamp message. Not used yet, just a placeholder for future versions.";
CM_ BO_ 129 "Emergency message of node SensorF with Node-ID 0x1";
CM_ BO_ 385 "Transmit PDO 1 of node SensorF with Node-ID 0x1";
CM_ SG_ 385 Sensor_TX_PodState_Target "Target PodState by State Machine.";
CM_ SG_ 385 Sensor_TX_PodState_Last "Last PodState by State Machine.";
CM_ SG_ 385 Sensor_TX_PodState "PodState by State Machine.";
CM_ BO_ 449 "Receive PDO 1 of node SensorF with Node-ID 0x1";
CM_ BO_ 513 "Data from Encoder front (PDO10)";
CM_ BO_ 577 "Receive PDO 2 of node SensorF with Node-ID 0x1.";
CM_ BO_ 641 "Transmit PDO 3 of node SensorF with Node-ID 0x1";
CM_ BO_ 705 "Receive PDO 3 of node SensorF with Node-ID 0x1.";
CM_ BO_ 769 "Transmit PDO 4 of node SensorF with Node-ID 0x1";
CM_ BO_ 833 "Receive PDO 4 of node SensorF with Node-ID 0x1.";
CM_ BO_ 897 "Transmit PDO 5 of node SensorF with Node-ID 0x1";
CM_ BO_ 961 "Transmit PDO 6 of node SensorF with Node-ID 0x1";
CM_ BO_ 1025 "Transmit PDO 7 of node SensorF with Node-ID 0x1";
CM_ SG_ 1025 Sensor_GyroFront_X "Slope of front IMU in X direction.";
CM_ SG_ 1025 Sensor_Vel_EncoderFront "Velocity of Wheel Encoder front.";
CM_ SG_ 1025 Sensor_Pos_EncoderFront "Position of Wheel Encoder front.";
CM_ BO_ 1089 "Transmit PDO 8 of node SensorF with Node-ID 0x1";
CM_ BO_ 1153 "Transmit PDO 9 of node SensorF with Node-ID 0x1";
CM_ BO_ 1217 "Transmit Acc_X, Acc_Y, Acc_Z and Gyro_Z of front IMU of node SensorF.";
CM_ SG_ 1217 Sensor_GyroFront_Z "Slope of front IMU in Z direction.";
CM_ SG_ 1217 Sensor_AccFront_Z "Acceleration of front IMU in Z direction.";
CM_ SG_ 1217 Sensor_AccFront_Y "Acceleration of front IMU in Y direction.";
CM_ SG_ 1217 Sensor_AccFront_X "Acceleration of front IMU in X direction.";
CM_ BO_ 1281 "SensorF with Node-ID 0x1 (PDO11).";
CM_ BO_ 1345 "Transmit PDO 12 of node SensorF with Node-ID 0x1.";
CM_ BO_ 1409 "DO NOT CHANGE ANYTHING HERE!
SDO Response of node SensorF with Node-ID 0x1";
CM_ SG_ 1409 Sensor_SDO_RespCode "Response code of SDO access.";
CM_ SG_ 1409 Sensor_SDO_ID "Specifies SDO-ID of SensorF";
CM_ BO_ 1473 "DO NOT CHANGE ANYTHING HERE!
SDO Request Upload to node SensorF with Node-ID 0x1";
CM_ SG_ 1473 Sensor_SDO_ID "Specifies SDO-ID of SensorF";
CM_ BO_ 1537 "DO NOT CHANGE ANYTHING HERE!
SDO Request Download from node SensorF with Node-ID 0x1";
CM_ SG_ 1537 Sensor_SDO_ID "Specifies SDO-ID of SensorF";
CM_ BO_ 1793 "Heartbeat of node SensorF with Node-ID 0x1";
CM_ SG_ 1793 Sensor_NodeState "Heartbeat status of node SensorF";
CM_ BO_ 1857 "Bootloader transmit from node SensorF with Node-ID 0x1";
CM_ BO_ 1921 "Bootloader receive by node SensorF with Node-ID 0x1";
CM_ BO_ 514 "Transmit PDO 2 of node SensorR with Node-ID 0x2. RunState, Enabled, ErrorFlag, TrajectorySet";
CM_ SG_ 514 Sensor_TX_ErrorFlag "Error status of SensorR.";
CM_ SG_ 514 Sensor_TX_Enabled "Enable status of SensorR.";
CM_ SG_ 514 Sensor_TX_TrajectorySet "Flag for trajectorySet";
CM_ SG_ 514 Sensor_TX_RunState "State of run of SensorR.";
CM_ BO_ 642 "Transmit PDO 3 of node SensorR with Node-ID 0x2. Filtered data after StateEstimation";
CM_ SG_ 642 Sensor_TX_Pos "Filtered position by StateEstimation.";
CM_ SG_ 642 Sensor_TX_Vel "Filtered velocity by StateEstimation.";
CM_ SG_ 642 Sensor_TX_Acc "Filtered acceleration by StateEstimation.";
CM_ BO_ 706 "Receive PDO 3 of node SensorR with Node-ID 0x2";
CM_ SG_ 706 Sensor_RX_ErrorReset "Error reset signal for SensorR.";
CM_ SG_ 706 Sensor_RX_Enable "Enable signal for SensorR.";
CM_ SG_ 706 Sensor_RX_LaunchComm "Launch Command of SensorR.";
CM_ BO_ 770 "Transmit PDO 4 of node SensorR with Node-ID 0x2. Velocity of EncoderFront, rear and optical, Stripes";
CM_ SG_ 770 Sensor_TX_Vel_Optical "Velocity of optical Sensor.";
CM_ SG_ 770 Sensor_TX_Vel_EncoderRear "Velocity of Wheel Encoder rear.";
CM_ SG_ 770 Sensor_TX_Vel_EncoderFront "Velocity of Wheel Encoder front.";
CM_ BO_ 898 "Transmit PDO 5 of node SensorR with Node-ID 0x2. Gyroscope data of IMU front and rear in X and Y direction.";
CM_ SG_ 898 Sensor_TX_GyroRear_Y "Slope of rear IMU in Y direction.";
CM_ SG_ 898 Sensor_TX_GyroRear_X "Slope of rear IMU in X direction.";
CM_ SG_ 898 Sensor_TX_GyroFront_Y "Slope of front IMU in Y direction.";
CM_ SG_ 898 Sensor_TX_GyroFront_X "Slope of front IMU in X direction.";
CM_ BO_ 962 "Transmit PDO 6 of node SensorR with Node-ID 0x2";
CM_ BO_ 1090 "Transmit PDO 8 of node SensorR with Node-ID 0x2";
CM_ BO_ 1218 "Transmit PDO 10 of node SensorR with Node-ID 0x2. Send acceleration of IMU Rear.";
CM_ SG_ 1218 Sensor_TX_GyroRear_Z "Slope of rear IMU in Z direction.";
CM_ SG_ 1218 Sensor_TX_AccRear_Z "Acceleration of rear IMU in Z direction.";
CM_ SG_ 1218 Sensor_TX_AccRear_Y "Acceleration of rear IMU in Y direction.";
CM_ SG_ 1218 Sensor_TX_AccRear_X "Acceleration of rear IMU in X direction.";
CM_ BO_ 1282 "Transmit PDO 11 of node SensorR with Node-ID 0x2. Send position data of Encoder front, rear and optical and Stripes.";
CM_ SG_ 1282 Sensor_TX_StripeCounter_Right "Counting reflectors on the right site.";
CM_ SG_ 1282 Sensor_TX_StripeCounter_Left "Counting reflectors on the left site.";
CM_ SG_ 1282 Sensor_TX_Pos_Optical "Position of optical Sensor.";
CM_ SG_ 1282 Sensor_TX_Pos_EncoderRear "Position of Wheel Encoder rear.";
CM_ SG_ 1282 Sensor_TX_Pos_EncoderFront "Position of Wheel Encoder front.";
CM_ BO_ 145 "Emergency message of node BrakeF with Node-ID 0x11";
CM_ BO_ 401 "Transmit PDO 1 of node BrakeF with Node-ID 0x11";
CM_ SG_ 401 Brake_TX_SDC_Input "Sends the current value of the SDC received by BrakeF.
";
CM_ SG_ 401 Brake_TX_ErrorFlag "Error status of BrakeF.";
CM_ SG_ 401 Brake_TX_Enabled "Enable status of BrakeF.";
CM_ SG_ 401 Brake_TX_Status "Status signal of BrakeF.";
CM_ BO_ 465 "Receive PDO 1 of node BrakeF with Node-ID 0x11";
CM_ SG_ 465 Brake_RX_Engage "Engage signal for BrakeF.";
CM_ SG_ 465 Brake_RX_Enable "Enable signal for BrakeF.";
CM_ SG_ 465 Brake_RX_ErrorReset "Error reset signal for BrakeF.";
CM_ BO_ 529 "Transmit PDO 2 of node BrakeF with Node-ID 0x11";
CM_ BO_ 593 "Receive PDO 2 of node BrakeF with Node-ID 0x11";
CM_ BO_ 657 "Transmit PDO 3 of node BrakeF with Node-ID 0x11";
CM_ BO_ 721 "Receive PDO 3 of node BrakeF with Node-ID 0x11";
CM_ BO_ 785 "Transmit PDO 4 of node BrakeF with Node-ID 0x11";
CM_ BO_ 849 "Receive PDO 4 of node BrakeF with Node-ID 0x11";
CM_ BO_ 913 "Transmit PDO 5 of node BrakeF with Node-ID 0x11";
CM_ BO_ 977 "Transmit PDO 6 of node BrakeF with Node-ID 0x11";
CM_ BO_ 1041 "Transmit PDO 7 of node BrakeF with Node-ID 0x11";
CM_ BO_ 1105 "Transmit PDO 8 of node BrakeF with Node-ID 0x11";
CM_ BO_ 1169 "Transmit PDO 9 of node BrakeF with Node-ID 0x11";
CM_ BO_ 1233 "Transmit PDO 10 of node BrakeF with Node-ID 0x11";
CM_ BO_ 1297 "Transmit PDO 11 of node BrakeF with Node-ID 0x11";
CM_ BO_ 1361 "Transmit PDO 12 of node BrakeF with Node-ID 0x11";
CM_ BO_ 1425 "DO NOT CHANGE ANYTHING HERE!
SDO Response of node BrakeF with Node-ID 0x11";
CM_ SG_ 1425 Brake_SDO_RespCode "Response code of SDO access.";
CM_ SG_ 1425 Brake_SDO_ID "Specifies SDO-ID of BrakeF";
CM_ BO_ 1489 "DO NOT CHANGE ANYTHING HERE!
SDO Request Upload to node BrakeF with Node-ID 0x11";
CM_ SG_ 1489 Brake_SDO_ID "Specifies SDO-ID of BrakeF";
CM_ BO_ 1553 "DO NOT CHANGE ANYTHING HERE!
SDO Request Download from node BrakeF with Node-ID 0x11";
CM_ SG_ 1553 Brake_SDO_ID "Specifies SDO-ID of BrakeF";
CM_ BO_ 1809 "Heartbeat of node BrakeF with Node-ID 0x11";
CM_ SG_ 1809 Brake_NodeState "Heartbeat status of node BrakeF";
CM_ BO_ 1873 "Bootloader transmit from node BrakeF with Node-ID 0x11";
CM_ BO_ 1937 "Bootloader receive by node BrakeF with Node-ID 0x11";
CM_ BO_ 154 "Emergency message of node PDU with Node-ID 0x1A";
CM_ BO_ 410 "Transmit PDO 1 of node PDU with Node-ID 0x1A";
CM_ SG_ 410 PDU_TX_PEHWEnabled "PE Hardware Enable status signal of PDU.";
CM_ SG_ 410 PDU_TX_ErrorFlag "Error status of PDU.";
CM_ SG_ 410 PDU_TX_Enabled "Enable status of PDU.";
CM_ BO_ 474 "Control message of the PDU sent by the State Machine.";
CM_ SG_ 474 PDU_RX_PEHWEnable "PE Hardware Enable signal of PDU.";
CM_ SG_ 474 PDU_RX_ErrorReset "Error reset signal for PDU.";
CM_ SG_ 474 PDU_RX_Enable "Enable signal for PDU.";
CM_ BO_ 538 "Transmit PDO 2 of node PDU with Node-ID 0x1A";
CM_ BO_ 602 "Dutycycle for the channels of the PDU that support PWM.";
CM_ BO_ 666 "Transmit PDO 3 of node PDU with Node-ID 0x1A";
CM_ BO_ 730 "Receive PDO 3 of node PDU with Node-ID 0x1A";
CM_ BO_ 794 "Transmit PDO 4 of node PDU with Node-ID 0x1A";
CM_ BO_ 858 "Receive PDO 4 of node PDU with Node-ID 0x1A";
CM_ BO_ 922 "Transmit PDO 5 of node PDU with Node-ID 0x1A";
CM_ BO_ 986 "Transmit PDO 6 of node PDU with Node-ID 0x1A";
CM_ BO_ 1050 "Transmit PDO 7 of node PDU with Node-ID 0x1A";
CM_ BO_ 1114 "Transmit PDO 8 of node PDU with Node-ID 0x1A";
CM_ BO_ 1178 "Transmit PDO 9 of node PDU with Node-ID 0x1A";
CM_ BO_ 1242 "Transmit PDO 10 of node PDU with Node-ID 0x1A";
CM_ BO_ 1306 "Transmit PDO 11 of node PDU with Node-ID 0x1A";
CM_ BO_ 1370 "Transmit PDO 12 of node PDU with Node-ID 0x1A";
CM_ BO_ 1434 "DO NOT CHANGE ANYTHING HERE!
SDO Response of node PDU with Node-ID 0x1A";
CM_ SG_ 1434 PDU_SDO_RespCode "Response code of SDO access.";
CM_ SG_ 1434 PDU_SDO_ID "Specifies SDO-ID of PDU";
CM_ BO_ 1498 "DO NOT CHANGE ANYTHING HERE!
SDO Request Upload to node PDU with Node-ID 0x1A";
CM_ SG_ 1498 PDU_SDO_ID "Specifies SDO-ID of PDU";
CM_ BO_ 1562 "DO NOT CHANGE ANYTHING HERE!
SDO Request Download from node PDU with Node-ID 0x1A";
CM_ SG_ 1562 PDU_SDO_ID "Specifies SDO-ID of PDU";
CM_ BO_ 1818 "Heartbeat of node PDU with Node-ID 0x1A";
CM_ SG_ 1818 PDU_NodeState "Heartbeat status of node PDU";
CM_ BO_ 1882 "Bootloader transmit from node PDU with Node-ID 0x1A";
CM_ BO_ 1946 "Bootloader receive by node PDU with Node-ID 0x1A";
CM_ BO_ 162 "Emergency message of node TelemetryNode with Node-ID 0x22";
CM_ BO_ 418 "Transmit PDO 1 of node TelemetryNode with Node-ID 0x22";
CM_ BO_ 482 "Receive PDO 1 of node TelemetryNode with Node-ID 0x22";
CM_ BO_ 546 "Transmit PDO 2 of node TelemetryNode with Node-ID 0x22";
CM_ BO_ 610 "Receive PDO 2 of node TelemetryNode with Node-ID 0x22";
CM_ BO_ 674 "Transmit PDO 3 of node TelemetryNode with Node-ID 0x22";
CM_ BO_ 738 "Receive PDO 3 of node TelemetryNode with Node-ID 0x22";
CM_ BO_ 802 "Transmit PDO 4 of node TelemetryNode with Node-ID 0x22";
CM_ BO_ 866 "Receive PDO 4 of node TelemetryNode with Node-ID 0x22";
CM_ BO_ 930 "Transmit PDO 5 of node TelemetryNode with Node-ID 0x22";
CM_ BO_ 994 "Transmit PDO 6 of node TelemetryNode with Node-ID 0x22";
CM_ BO_ 1058 "Transmit PDO 7 of node TelemetryNode with Node-ID 0x22";
CM_ BO_ 1122 "Transmit PDO 8 of node TelemetryNode with Node-ID 0x22";
CM_ BO_ 1186 "Transmit PDO 9 of node TelemetryNode with Node-ID 0x22";
CM_ BO_ 1250 "Transmit PDO 10 of node TelemetryNode with Node-ID 0x22";
CM_ BO_ 1314 "Transmit PDO 11 of node TelemetryNode with Node-ID 0x22";
CM_ BO_ 1378 "Transmit PDO 12 of node TelemetryNode with Node-ID 0x22";
CM_ BO_ 1442 "DO NOT CHANGE ANYTHING HERE!
SDO Response of node TelemetryNode with Node-ID 0x22";
CM_ SG_ 1442 TelemetryNode_SDO_RespCode "Response code of SDO access.";
CM_ SG_ 1442 TelemetryNode_SDO_ID "Specifies SDO-ID of TelemetryNode";
CM_ BO_ 1506 "DO NOT CHANGE ANYTHING HERE!
SDO Request Upload to node TelemetryNode with Node-ID 0x22";
CM_ SG_ 1506 TelemetryNode_SDO_ID "Specifies SDO-ID of TelemetryNode";
CM_ BO_ 1570 "DO NOT CHANGE ANYTHING HERE!
SDO Request Download from node TelemetryNode with Node-ID 0x22";
CM_ SG_ 1570 TelemetryNode_SDO_ID "Specifies SDO-ID of TelemetryNode";
CM_ BO_ 1826 "Heartbeat of node TelemetryNode with Node-ID 0x22";
CM_ SG_ 1826 TelemetryNode_NodeState "Heartbeat status of node TelemetryNode";
CM_ BO_ 1890 "Bootloader transmit from node TelemetryNode with Node-ID 0x22";
CM_ BO_ 1954 "Bootloader receive by node TelemetryNode with Node-ID 0x22";
BA_DEF_ SG_  "GenSigSendType" ENUM  "Cyclic","OnWrite","OnWriteWithRepetition","OnChange","OnChangeWithRepetition","IfActive","IfActiveWithRepetition","NoSigSendType";
BA_DEF_ BO_  "GenMsgSendType" ENUM  "Cyclic","not_used","not_used","not_used","not_used","Cyclic","not_used","IfActive","NoMsgSendType";
BA_DEF_  "BusType" STRING ;
BA_DEF_  "DBName" STRING ;
BA_DEF_ BO_  "GenMsgCycleTime" INT 2 50000;
BA_DEF_ BO_  "GenMsgDelayTime" INT 1 1000;
BA_DEF_ BO_  "GenMsgNrOfRepetitions" INT 1 999999;
BA_DEF_ SG_  "GenSigStartValue" FLOAT 0 100000000000;
BA_DEF_  "CANzero_ProtocolVersion" STRING ;
BA_DEF_  "CANzero_DBCVersion" INT 0 16777215;
BA_DEF_  "CANzero_SDOClientName" STRING ;
BA_DEF_  "CANzero_NMTMasterName" STRING ;
BA_DEF_ BU_  "CANzero_NodeID" HEX 0 63;
BA_DEF_ SG_  "CANzero_SDO_AccessType" ENUM  "Read Write","Read Only","Write Only";
BA_DEF_DEF_  "GenSigSendType" "Cyclic";
BA_DEF_DEF_  "GenMsgSendType" "NoMsgSendType";
BA_DEF_DEF_  "BusType" "";
BA_DEF_DEF_  "DBName" "";
BA_DEF_DEF_  "GenMsgCycleTime" 100;
BA_DEF_DEF_  "GenMsgDelayTime" 1;
BA_DEF_DEF_  "GenMsgNrOfRepetitions" 1;
BA_DEF_DEF_  "GenSigStartValue" 0;
BA_DEF_DEF_  "CANzero_ProtocolVersion" "";
BA_DEF_DEF_  "CANzero_DBCVersion" 0;
BA_DEF_DEF_  "CANzero_SDOClientName" "Master";
BA_DEF_DEF_  "CANzero_NMTMasterName" "Master";
BA_DEF_DEF_  "CANzero_NodeID" 0;
BA_DEF_DEF_  "CANzero_SDO_AccessType" "Read Write";
BA_ "CANzero_SDOClientName" "TelemetryNode";
BA_ "CANzero_DBCVersion" 149;
BA_ "CANzero_ProtocolVersion" "V1.0";
BA_ "BusType" "CAN";
BA_ "DBName" "pod2022";
BA_ "CANzero_NodeID" BU_ TelemetryNode 34;
BA_ "CANzero_NodeID" BU_ Sensor 1;
BA_ "CANzero_NodeID" BU_ Brake 17;
BA_ "CANzero_NodeID" BU_ PDU 26;
BA_ "GenSigStartValue" SG_ 1089 Sensor_TX_BatteryTemp 600;
BA_ "GenSigStartValue" SG_ 1153 Sensor_Cooling_Temp 600;
BA_ "GenSigStartValue" SG_ 1153 Sensor_LIMT_Stator_4 266.666666666667;
BA_ "GenSigStartValue" SG_ 1153 Sensor_LIMT_Stator_3 266.666666666667;
BA_ "GenSigStartValue" SG_ 1153 Sensor_LIMT_Stator_2 266.666666666667;
BA_ "GenSigStartValue" SG_ 1153 Sensor_LIMT_Stator_1 266.666666666667;
BA_ "GenSigStartValue" SG_ 1041 Brake_TX_Pressure_Tank 400;
BA_ "GenSigStartValue" SG_ 1041 Brake_TX_Pressure_Retract 400;
BA_ "GenSigStartValue" SG_ 1041 Brake_TX_Pressure_Act 400;
BA_ "GenSigStartValue" SG_ 602 PDU_LPCh9_Dutycycle 200;
BA_ "GenSigStartValue" SG_ 602 PDU_LPCh8_Dutycycle 200;
BA_ "GenSigStartValue" SG_ 602 PDU_LPCh3_Dutycycle 200;
BA_ "GenSigStartValue" SG_ 602 PDU_LPCh2_Dutycycle 200;
BA_ "GenSigStartValue" SG_ 602 PDU_LPCh10_Dutycycle 200;
BA_ "GenSigStartValue" SG_ 602 PDU_LPCh1_Dutycycle 200;
BA_ "GenSigStartValue" SG_ 730 PDU_D4_Dutycycle 200;
BA_ "GenSigStartValue" SG_ 730 PDU_D3_Dutycycle 200;
BA_ "GenSigStartValue" SG_ 730 PDU_D2_Dutycycle 200;
BA_ "GenSigStartValue" SG_ 730 PDU_D1_Dutycycle 200;
BA_ "GenSigStartValue" SG_ 730 PDU_HPCh2_Dutycycle 200;
BA_ "GenSigStartValue" SG_ 730 PDU_HPCh1_Dutycycle 200;
VAL_ 386 Sensor_TX_PodState_Target 7 "Pod Safe to Approach" 6 "Pod Pushable" 5 "Pod Launching" 4 "Pod Ready to Launch" 3 "Pod Fault" 2 "Pod Launch Preparation" 1 "Pod Idle" 0 "Pod Off" ;
VAL_ 386 Sensor_TX_PodState_Last 7 "Pod Safe to Approach" 6 "Pod Pushable" 5 "Pod Launching" 4 "Pod Ready to Launch" 3 "Pod Fault" 2 "Pod Launch Preparation" 1 "Pod Idle" 0 "Pod Off" ;
VAL_ 386 Sensor_TX_PodState 7 "Pod Safe to Approach" 6 "Pod Pushable" 5 "Pod Launching" 4 "Pod Ready to Launch" 3 "Pod Fault" 2 "Pod Launch Preparation" 1 "Pod Idle" 0 "Pod Off" ;
VAL_ 2684354556 OpticalSensor_TX_LEDStatus 2 "FLASH" 1 "ON" 0 "OFF" ;
VAL_ 2 CANzero_NMT_Node 0 "All" 1 "SensorF" 2 "SensorR" 17 "BrakeF" 18 "BrakeR" 26 "PDU" 10 "HVCU" 25 "HVTU" 34 "TelemetryNode" ;
VAL_ 2 CANzero_NMT_State 1 "Start Remote Node" 2 "Stop Remote Node" 128 "Enter Pre-Operational" 129 "Reset" ;
VAL_ 385 Sensor_TX_PodState_Target 7 "Pod Safe to Approach" 6 "Pod Pushable" 5 "Pod Launching" 4 "Pod Ready to Launch" 3 "Pod Fault" 2 "Pod Launch Preparation" 1 "Pod Idle" 0 "Pod Off" ;
VAL_ 385 Sensor_TX_PodState_Last 7 "Pod Safe to Approach" 6 "Pod Pushable" 5 "Pod Launching" 4 "Pod Ready to Launch" 3 "Pod Fault" 2 "Pod Launch Preparation" 1 "Pod Idle" 0 "Pod Off" ;
VAL_ 385 Sensor_TX_PodState 7 "Pod Safe to Approach" 6 "Pod Pushable" 5 "Pod Launching" 4 "Pod Ready to Launch" 3 "Pod Fault" 2 "Pod Launch Preparation" 1 "Pod Idle" 0 "Pod Off" ;
VAL_ 513 Sensor_TX_PreopHVCUT 1 "Transition" 0 "No Transitions" ;
VAL_ 513 Sensor_TX_PreopPDUT 1 "Transition" 0 "No Transitions" ;
VAL_ 513 Sensor_TX_PreopBrakeRT 1 "Transition" 0 "No Transitions" ;
VAL_ 513 Sensor_TX_PreopBrakeFT 1 "Transition" 0 "No Transitions" ;
VAL_ 513 Sensor_TX_PreopSensorRT 1 "Transition" 0 "No Transitions" ;
VAL_ 513 Sensor_TX_EnableSensorRT 1 "Transition" 0 "No Transitions" ;
VAL_ 513 Sensor_TX_EnablePDUT 1 "Transition" 0 "No Transitions" ;
VAL_ 513 Sensor_TX_EnableHVCUT 1 "Transition" 0 "No Transitions" ;
VAL_ 513 Sensor_TX_EnableBrakeRT 1 "Transition" 0 "No Transitions" ;
VAL_ 513 Sensor_TX_EnableBrakeFT 1 "Transition" 0 "No Transitions" ;
VAL_ 513 Sensor_TX_SetHVTransition 1 "Transition" 0 "No Transitions" ;
VAL_ 513 Sensor_TX_PreopTransition 1 "Transition" 0 "No Transitions" ;
VAL_ 513 Sensor_TX_LaunchStartTransition 1 "Transition" 0 "No Transitions" ;
VAL_ 513 Sensor_TX_LaunchSetupTransition 1 "Transition" 0 "No Transitions" ;
VAL_ 513 Sensor_TX_HWEnableTransition 1 "Transition" 0 "No Transitions" ;
VAL_ 513 Sensor_TX_ErrorResetTransition 1 "Transition" 0 "No Transitions" ;
VAL_ 513 Sensor_TX_EnableTransition 1 "Transition" 0 "No Transitions" ;
VAL_ 513 Sensor_TX_BrakesTransition 1 "Transition" 0 "No Transitions" ;
VAL_ 1409 Sensor_SDO_RespCode 5 "ERR: Out of range" 4 "ERR: No access in this state" 3 "ERR: Read only object" 2 "ERR: Write only object" 1 "ERR: Non existing object" 0 "OK" ;
VAL_ 1409 Sensor_SDO_ID 0 "Reserved" ;
VAL_ 1473 Sensor_SDO_ID 0 "Reserved" ;
VAL_ 1537 Sensor_SDO_ID 0 "Reserved" ;
VAL_ 1793 Sensor_NodeState 0 "Bootup" 4 "Stopped" 5 "Operational" 127 "Pre-Operational" ;
VAL_ 514 Sensor_TX_ErrorFlag 1 "Error" 0 "No Error" ;
VAL_ 514 Sensor_TX_Enabled 1 "Enabled" 0 "Disabled" ;
VAL_ 514 Sensor_TX_TrajectorySet 2 "Invalid set" 1 "Set" 0 "Not set" ;
VAL_ 514 Sensor_TX_RunState 4 "Idle not ready" 3 "Launch Abort" 2 "Finished" 1 "Ready to Launch" 0 "Launching" ;
VAL_ 706 Sensor_RX_ErrorReset 1 "Reset" 0 "No Reset" ;
VAL_ 706 Sensor_RX_Enable 1 "Enable" 0 "Disable" ;
VAL_ 706 Sensor_RX_LaunchComm 2 "No Start" 1 "Abort Launch" 0 "Start Launch" ;
VAL_ 401 Brake_TX_SDC_Input 1 "Closed" 0 "Open" ;
VAL_ 401 Brake_TX_ErrorFlag 1 "Error" 0 "No Error" ;
VAL_ 401 Brake_TX_Enabled 1 "Enabled" 0 "Disabled" ;
VAL_ 401 Brake_TX_Status 2 "EngagedService" 1 "EngagedEmergency" 0 "Disengaged" ;
VAL_ 465 Brake_RX_Engage 2 "EngageService" 1 "EngageEmergency" 0 "Disengage" ;
VAL_ 465 Brake_RX_Enable 1 "Enable" 0 "Disable" ;
VAL_ 465 Brake_RX_ErrorReset 1 "Reset" 0 "No Reset" ;
VAL_ 1425 Brake_SDO_RespCode 5 "ERR: Out of range" 4 "ERR: No access in this state" 3 "ERR: Read only object" 2 "ERR: Write only object" 1 "ERR: Non existing object" 0 "OK" ;
VAL_ 1425 Brake_SDO_ID 0 "Reserved" ;
VAL_ 1489 Brake_SDO_ID 0 "Reserved" ;
VAL_ 1553 Brake_SDO_ID 0 "Reserved" ;
VAL_ 1809 Brake_NodeState 0 "Bootup" 4 "Stopped" 5 "Operational" 127 "Pre-Operational" ;
VAL_ 410 PDU_TX_PEHWEnabled 1 "Enabled" 0 "Disabled" ;
VAL_ 410 PDU_TX_ErrorFlag 1 "Error" 0 "No Error" ;
VAL_ 410 PDU_TX_Enabled 1 "Enabled" 0 "Disabled" ;
VAL_ 474 PDU_RX_PEHWEnable 1 "Enable" 0 "Disable" ;
VAL_ 474 PDU_RX_ErrorReset 1 "Reset" 0 "No Reset" ;
VAL_ 474 PDU_RX_Enable 1 "Enable" 0 "Disable" ;
VAL_ 1178 PDU_LPCh1_State 3 "External Voltage" 2 "Output Short Circuit" 1 "Status Change Pending" 0 "OK" ;
VAL_ 1434 PDU_SDO_RespCode 5 "ERR: Out of range" 4 "ERR: No access in this state" 3 "ERR: Read only object" 2 "ERR: Write only object" 1 "ERR: Non existing object" 0 "OK" ;
VAL_ 1434 PDU_SDO_ID 0 "Reserved" ;
VAL_ 1498 PDU_SDO_ID 0 "Reserved" ;
VAL_ 1562 PDU_SDO_ID 0 "Reserved" ;
VAL_ 1818 PDU_NodeState 0 "Bootup" 4 "Stopped" 5 "Operational" 127 "Pre-Operational" ;
VAL_ 482 TelemetryNode_RX_Shutdown 2 "Reboot" 1 "Shutdown" 0 "None" ;
VAL_ 1442 TelemetryNode_SDO_RespCode 5 "ERR: Out of range" 4 "ERR: No access in this state" 3 "ERR: Read only object" 2 "ERR: Write only object" 1 "ERR: Non existing object" 0 "OK" ;
VAL_ 1442 TelemetryNode_SDO_ID 0 "Reserved" ;
VAL_ 1506 TelemetryNode_SDO_ID 0 "Reserved" ;
VAL_ 1570 TelemetryNode_SDO_ID 0 "Reserved" ;
VAL_ 1826 TelemetryNode_NodeState 0 "Bootup" 4 "Stopped" 5 "Operational" 127 "Pre-Operational" ;
